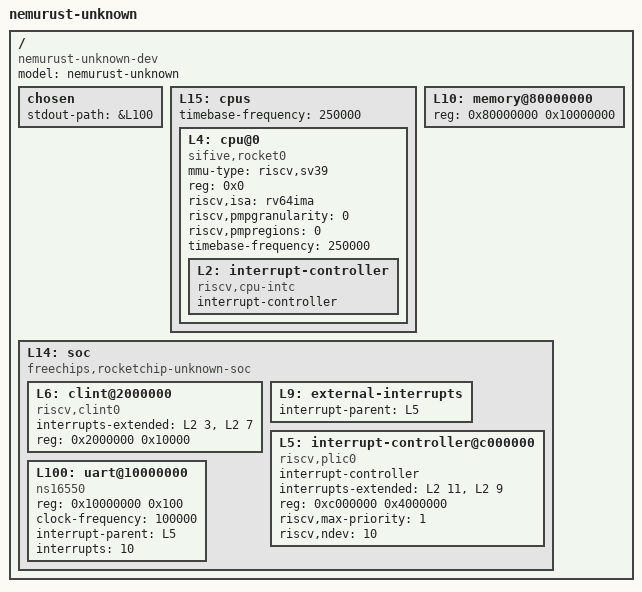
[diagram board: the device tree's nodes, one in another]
/dts-v1/;
/ {
	#address-cells = <1>;
	#size-cells = <1>;
	compatible = "nemurust-unknown-dev";
	model = "nemurust-unknown";
	
	chosen {
    		stdout-path = &L100;
	};
	L15: cpus {
		#address-cells = <1>;
		#size-cells = <0>;
		timebase-frequency = <250000>;
		L4: cpu@0 {
			compatible = "sifive,rocket0", "riscv";
			device_type = "cpu";
			mmu-type = "riscv,sv39";
			reg = <0x0>;
			riscv,isa = "rv64ima";
			riscv,pmpgranularity = <0>;
			riscv,pmpregions = <0>;
			status = "okay";
			timebase-frequency = <250000>;
			L2: interrupt-controller {
				#interrupt-cells = <1>;
				compatible = "riscv,cpu-intc";
				interrupt-controller;
			};
		};
	};
	L10: memory@80000000 {
		device_type = "memory";
		reg = <0x80000000 0x10000000>;
	};
	L14: soc {
		#address-cells = <1>;
		#size-cells = <1>;
		compatible = "freechips,rocketchip-unknown-soc", "simple-bus";
		ranges;
		L6: clint@2000000 {
			compatible = "riscv,clint0";
			interrupts-extended = <&L2 3 &L2 7>;
			reg = <0x2000000 0x10000>;
			reg-names = "control";
		};
		L9: external-interrupts {
            interrupt-parent = <&L5>;
        };
        L5: interrupt-controller@c000000 {
            #interrupt-cells = <1>;
            compatible = "riscv,plic0";
            interrupt-controller;
            interrupts-extended = <&L2 11 &L2 9>;
            reg = <0xc000000 0x4000000>;
            reg-names = "control";
            riscv,max-priority = <1>;
            riscv,ndev = <10>;
        };
		L100: uart@10000000 {
		    device_type = "serial";
		    compatible = "ns16550";
		    reg = <0x10000000 0x100>;
            clock-frequency = <100000>;
            interrupt-parent = <&L5>;
            interrupts = <10>;
		};
	};
};
